AUTOSAR XML (schema 314)
package /ComponentType
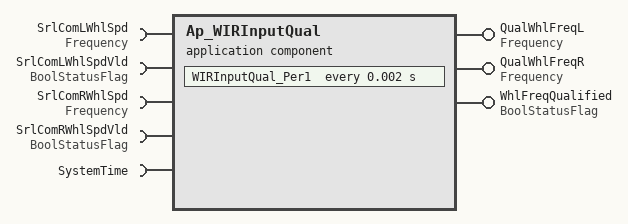
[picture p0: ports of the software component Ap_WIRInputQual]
  application software component type Ap_WIRInputQual
    provide port QualWhlFreqL: unqueued-sender-com-spec{data-element=Hz_f32, can-invalidate=false, init-value=D_ZERO_ULS_F32}, provided-interface=Frequency
    provide port QualWhlFreqR: unqueued-sender-com-spec{data-element=Hz_f32, can-invalidate=false, init-value=D_ZERO_ULS_F32}, provided-interface=Frequency
    provide port WhlFreqQualified: unqueued-sender-com-spec{data-element=Cnt_lgc, can-invalidate=false, init-value=D_TRUE_CNT_LGC}, provided-interface=BoolStatusFlag
    5 x require port:
      SrlComLWhlSpd: unqueued-receiver-com-spec{data-element=Hz_f32, init-value=D_ZERO_ULS_F32}, required-interface=Frequency
      SrlComLWhlSpdVld: unqueued-receiver-com-spec{data-element=Cnt_lgc, init-value=D_FALSE_CNT_LGC}, required-interface=BoolStatusFlag
      SrlComRWhlSpd: unqueued-receiver-com-spec{data-element=Hz_f32, init-value=D_ZERO_ULS_F32}, required-interface=Frequency
      SrlComRWhlSpdVld: unqueued-receiver-com-spec{data-element=Cnt_lgc, init-value=D_FALSE_CNT_LGC}, required-interface=BoolStatusFlag
      SystemTime: required-interface=SystemTime
        required-com-specs:
          DtrmnElapsedTime_mS_u16
          DtrmnElapsedTime_mS_u32
          DtrmnElapsedTime_uS_u16
          DtrmnElapsedTime_uS_u32
          GetSystemTime_mS_u32
          GetSystemTime_uS_u32
  internal behavior Ap_WIRInputQual_InternalBehavior: component=Ap_WIRInputQual
    timing event TMT_WIRInputQual_Per1: start-on-event=WIRInputQual_Per1, period=0.002
    port-api-options:
      enable-take-address=false, indirect-api=false, port=QualWhlFreqL
      enable-take-address=false, indirect-api=false, port=QualWhlFreqR
      enable-take-address=false, indirect-api=false, port=SrlComLWhlSpd
      enable-take-address=false, indirect-api=false, port=SrlComLWhlSpdVld
      enable-take-address=false, indirect-api=false, port=SrlComRWhlSpd
      enable-take-address=false, indirect-api=false, port=SrlComRWhlSpdVld
      enable-take-address=false, indirect-api=false, port=SystemTime
      enable-take-address=false, indirect-api=false, port=WhlFreqQualified
    runnable WIRInputQual_Per1
      4 x data read access:
        READ_SrlComLWhlSpd_Hz_f32: data-element=SrlComLWhlSpd.Hz_f32
        READ_SrlComLWhlSpdVld_Cnt_lgc: data-element=SrlComLWhlSpdVld.Cnt_lgc
        READ_SrlComRWhlSpd_Hz_f32: data-element=SrlComRWhlSpd.Hz_f32
        READ_SrlComRWhlSpdVld_Cnt_lgc: data-element=SrlComRWhlSpdVld.Cnt_lgc
      data write access WRITE_QualWhlFreqL_Hz_f32: data-element=QualWhlFreqL.Hz_f32
      data write access WRITE_QualWhlFreqR_Hz_f32: data-element=QualWhlFreqR.Hz_f32
      data write access WRITE_WhlFreqQualified_Cnt_lgc: data-element=WhlFreqQualified.Cnt_lgc
      sync call SC_SystemTime_DtrmnElapsedTime_mS_u16: operation=SystemTime.DtrmnElapsedTime_mS_u16, timeout=0
      sync call SC_SystemTime_GetSystemTime_mS_u32: operation=SystemTime.GetSystemTime_mS_u32, timeout=0
  swc implementation Ap_WIRInputQual_Implementation: behavior=Ap_WIRInputQual_InternalBehavior
    code-descriptors:
      code Code: type=SRC
